AUTOSAR XML (schema 4.0)
standard types defined: float32, float64, sint16, sint32, sint8, uint16, uint32, uint8, void, boolean
package /ImplDataTypes
  impl type Impl_SensorPositionType: implementation-data-type=uint8, type-emitter=RTE
  impl type Impl_SensorWeightType: implementation-data-type=uint8, type-emitter=RTE
  impl type Impl_StepMotorStepType: implementation-data-type=uint8, type-emitter=RTE
package /MappingSets
  data type mapping set MappingSet
package /PortInterfaces/ClientServer
  client server interface CsIf_PositionSensor
    operation GetPosition
      arg position: type=Impl_SensorPositionType, direction=OUT
  client server interface CsIf_StepMotor
    operation Move
      arg step: type=Impl_StepMotorStepType, direction=IN
  client server interface CsIf_WeightSensor
    operation GetWeight
      arg weight: type=Impl_SensorWeightType, direction=OUT
package /SoftwareComponents
  8 x swc implementation, all with programming-language=C, sw-version=1.0.0, vendor-id=255:
    Impl_SWC_HeightMotor: behavior=Ibhv_SWC_HeightMotor
      code-descriptors:
        code Code: artifact-descriptors=autosar-engineering-object={short-label=SWC.c, category=SWSRC}
      resource consumption ResourceConsumption
    Impl_SWC_HeightSensor: behavior=Ibhv_SWC_HeightSensor
      code-descriptors:
        code Code: artifact-descriptors=autosar-engineering-object={short-label=SWC.c, category=SWSRC}
      resource consumption ResourceConsumption
    Impl_SWC_InclineMotor: behavior=Ibhv_SWC_InclineMotor
      code-descriptors:
        code Code: artifact-descriptors=autosar-engineering-object={short-label=SWC.c, category=SWSRC}
      resource consumption ResourceConsumption
    Impl_SWC_InclineSensor: behavior=Ibhv_SWC_InclineSensor
      code-descriptors:
        code Code: artifact-descriptors=autosar-engineering-object={short-label=SWC.c, category=SWSRC}
      resource consumption ResourceConsumption
    Impl_SWC_SeatManager: behavior=Ibhv_SWC_SeatManager
      code-descriptors:
        code Code: artifact-descriptors=autosar-engineering-object={short-label=SWC.c, category=SWSRC}
      resource consumption ResourceConsumption
    Impl_SWC_SlideMotor: behavior=Ibhv_SWC_SlideMotor
      code-descriptors:
        code Code: artifact-descriptors=autosar-engineering-object={short-label=SWC.c, category=SWSRC}
      resource consumption ResourceConsumption
    Impl_SWC_SlideSensor: behavior=Ibhv_SWC_SlideSensor
      code-descriptors:
        code Code: artifact-descriptors=autosar-engineering-object={short-label=SWC.c, category=SWSRC}
      resource consumption ResourceConsumption
    Impl_SWC_WeightSensor: behavior=Ibhv_SWC_WeightSensor
      code-descriptors:
        code Code: artifact-descriptors=autosar-engineering-object={short-label=SWC.c, category=SWSRC}
      resource consumption ResourceConsumption
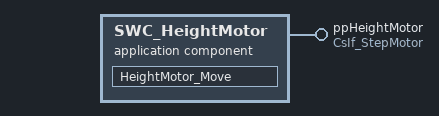
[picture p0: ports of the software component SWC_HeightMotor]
  application sw component type SWC_HeightMotor
    provide port ppHeightMotor: provided-interface=CsIf_StepMotor
    behavior Ibhv_SWC_HeightMotor: data-type-mapping=MappingSet, handle-termination-and-restart=NO-SUPPORT
      operation invoked event OIE_ppHeightMotor_Move: start-on-event=HeightMotor_Move, operation=ppHeightMotor.Move
      runnable HeightMotor_Move
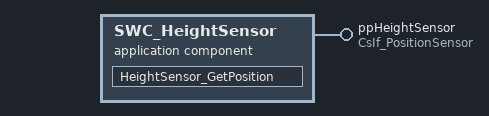
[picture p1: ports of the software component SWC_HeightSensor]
  application sw component type SWC_HeightSensor
    provide port ppHeightSensor: provided-interface=CsIf_PositionSensor
    behavior Ibhv_SWC_HeightSensor: data-type-mapping=MappingSet, handle-termination-and-restart=NO-SUPPORT
      operation invoked event OIE_ppHeightSensor_GetPosition: start-on-event=HeightSensor_GetPosition, operation=ppHeightSensor.GetPosition
      runnable HeightSensor_GetPosition
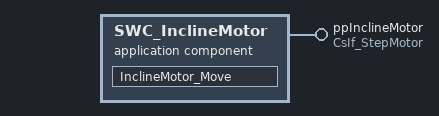
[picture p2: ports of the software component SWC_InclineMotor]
  application sw component type SWC_InclineMotor
    provide port ppInclineMotor: provided-interface=CsIf_StepMotor
    behavior Ibhv_SWC_InclineMotor: data-type-mapping=MappingSet, handle-termination-and-restart=NO-SUPPORT
      operation invoked event OIE_ppInclineMotor_Move: start-on-event=InclineMotor_Move, operation=ppInclineMotor.Move
      runnable InclineMotor_Move
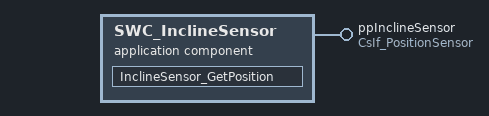
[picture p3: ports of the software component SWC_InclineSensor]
  application sw component type SWC_InclineSensor
    provide port ppInclineSensor: provided-interface=CsIf_PositionSensor
    behavior Ibhv_SWC_InclineSensor: data-type-mapping=MappingSet, handle-termination-and-restart=NO-SUPPORT
      operation invoked event OIE_ppInclineSensor_GetPosition: start-on-event=InclineSensor_GetPosition, operation=ppInclineSensor.GetPosition
      runnable InclineSensor_GetPosition
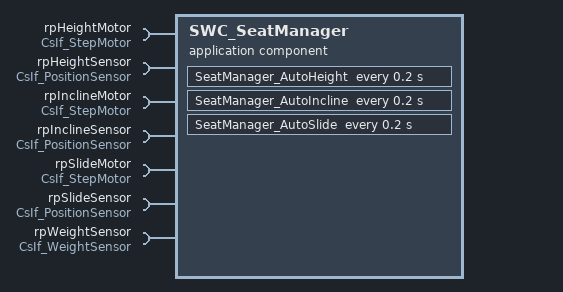
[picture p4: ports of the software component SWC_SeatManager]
  application sw component type SWC_SeatManager
    7 x require port:
      rpHeightMotor: required-interface=CsIf_StepMotor
      rpHeightSensor: required-interface=CsIf_PositionSensor
      rpInclineMotor: required-interface=CsIf_StepMotor
      rpInclineSensor: required-interface=CsIf_PositionSensor
      rpSlideMotor: required-interface=CsIf_StepMotor
      rpSlideSensor: required-interface=CsIf_PositionSensor
      rpWeightSensor: required-interface=CsIf_WeightSensor
    behavior Ibhv_SWC_SeatManager: data-type-mapping=MappingSet, handle-termination-and-restart=NO-SUPPORT
      timing event TE_SeatManager_AutoHeight_200ms: start-on-event=SeatManager_AutoHeight, period=0.2
      timing event TE_SeatManager_AutoIncline_200ms: start-on-event=SeatManager_AutoIncline, period=0.2
      timing event TE_SeatManager_AutoSlide_200ms: start-on-event=SeatManager_AutoSlide, period=0.2
      runnable SeatManager_AutoHeight
        sync call SCP_rpHeightMotor_Move: operation=rpHeightMotor.Move, timeout=0.0
        sync call SCP_rpHeightSensor_GetPosition: operation=rpHeightSensor.GetPosition, timeout=0.0
        sync call SCP_rpWeightSensor_GetWeight: operation=rpWeightSensor.GetWeight, timeout=0.0
      runnable SeatManager_AutoIncline
        sync call SCP_rpInclineMotor_Move: operation=rpInclineMotor.Move, timeout=0.0
        sync call SCP_rpInclineSensor_GetPosition: operation=rpInclineSensor.GetPosition, timeout=0.0
        sync call SCP_rpWeightSensor_GetWeight: operation=rpWeightSensor.GetWeight, timeout=0.0
      runnable SeatManager_AutoSlide
        sync call SCP_rpSlideMotor_Move: operation=rpSlideMotor.Move, timeout=0.0
        sync call SCP_rpSlideSensor_GetPosition: operation=rpSlideSensor.GetPosition, timeout=0.0
        sync call SCP_rpWeightSensor_GetWeight: operation=rpWeightSensor.GetWeight, timeout=0.0
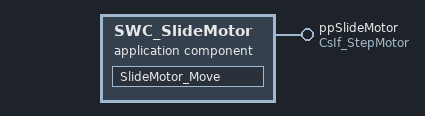
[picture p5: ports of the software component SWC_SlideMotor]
  application sw component type SWC_SlideMotor
    provide port ppSlideMotor: provided-interface=CsIf_StepMotor
    behavior Ibhv_SWC_SlideMotor: data-type-mapping=MappingSet, handle-termination-and-restart=NO-SUPPORT
      operation invoked event OIE_ppSlideMotor_Move: start-on-event=SlideMotor_Move, operation=ppSlideMotor.Move
      runnable SlideMotor_Move
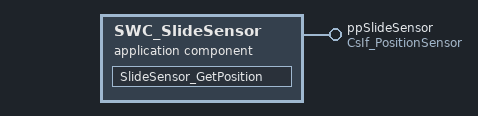
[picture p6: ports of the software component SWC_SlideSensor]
  application sw component type SWC_SlideSensor
    provide port ppSlideSensor: provided-interface=CsIf_PositionSensor
    behavior Ibhv_SWC_SlideSensor: data-type-mapping=MappingSet, handle-termination-and-restart=NO-SUPPORT
      operation invoked event OIE_ppSlideSensor_GetPosition: start-on-event=SlideSensor_GetPosition, operation=ppSlideSensor.GetPosition
      runnable SlideSensor_GetPosition
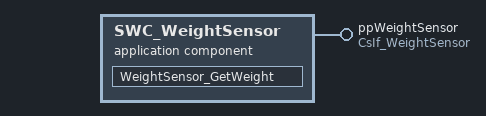
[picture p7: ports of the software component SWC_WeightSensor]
  application sw component type SWC_WeightSensor
    provide port ppWeightSensor: provided-interface=CsIf_WeightSensor
    behavior Ibhv_SWC_WeightSensor: data-type-mapping=MappingSet, handle-termination-and-restart=NO-SUPPORT
      operation invoked event OIE_ppWeightSensor_GetWeight: start-on-event=WeightSensor_GetWeight, operation=ppWeightSensor.GetWeight
      runnable WeightSensor_GetWeight
package /Compositions
  composition sw component type sensors taskComposition
    5 x component:
      SWC_HeightSensor: type=SWC_HeightSensor
      SWC_InclineSensor: type=SWC_InclineSensor
      SWC_SeatManager: type=SWC_SeatManager
      SWC_SlideSensor: type=SWC_SlideSensor
      SWC_WeightSensor: type=SWC_WeightSensor
    connect SWC_HeightSensor.ppHeightSensor -> SWC_SeatManager.rpHeightSensor
    connect SWC_InclineSensor.ppInclineSensor -> SWC_SeatManager.rpInclineSensor
    connect SWC_SlideSensor.ppSlideSensor -> SWC_SeatManager.rpSlideSensor
    connect SWC_WeightSensor.ppWeightSensor -> SWC_SeatManager.rpWeightSensor
